# K1921VK035 register map
Vendor: NIIET; Series: K1921VKx; File version: 2.10
CPU: CM4 r0p1, little endian, MPU, FPU, 3 interrupt priority bits
Registers are 32-bit, read-write, reset 0x0 unless marked. A register's access mark holds for its fields unless they carry their own. Offsets are from the block's base; [hi:lo] are bit positions; lines under a group give offsets from that group; {n}, {i} and the like mark numbered series; 'fields as' and 'values as' point back to an identical list.

## RCU — Reset and clock unit registers
Base 0x40041000
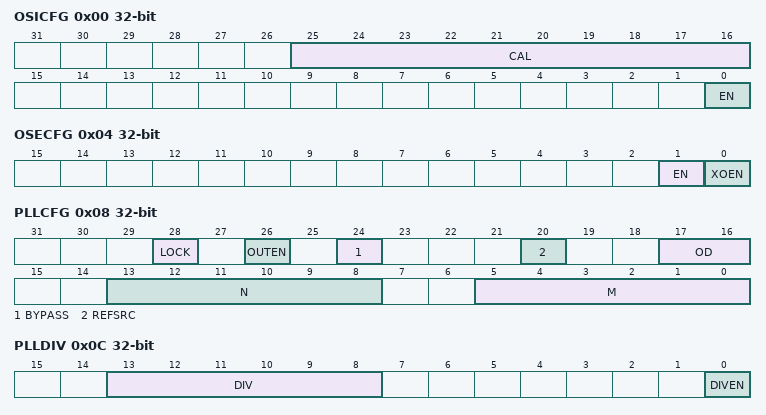
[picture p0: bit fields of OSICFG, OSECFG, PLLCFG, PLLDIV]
0x00 OSICFG — Internal oscillator configuration register
  [25:16] CAL — Oscillator 8MHz calibration value
  [0] EN — Oscillator 8MHz enable
0x04 OSECFG — External oscillator configuration register
  [1] EN — Enable external oscallator
  [0] XOEN — Enable output XO_OSC from external oscillator
0x08 PLLCFG — PLL configuration register
  [28] LOCK ro — PLL status lock
  [26] OUTEN — Enable PLL out
  [24] BYPASS — PLL Bypass enable
  [20] REFSRC — PLL Reference source select bit
    0=OSECLK (external oscillator); 1=OSICLK (internal oscillator)
  [17:16] OD — PLL OD Coefficient
    0=disabled; 1=Div2 (divide by 2); 2=Div4 (divide by 4); 3=Div8 (divide by 8)
  [13:8] N — PLL N Coefficient
  [5:0] M — PLL M Coefficient
0x0C PLLDIV — PLL divider register
  [13:8] DIV — PLL divider coefficent
  [0] DIVEN — PLL Divider enable bit
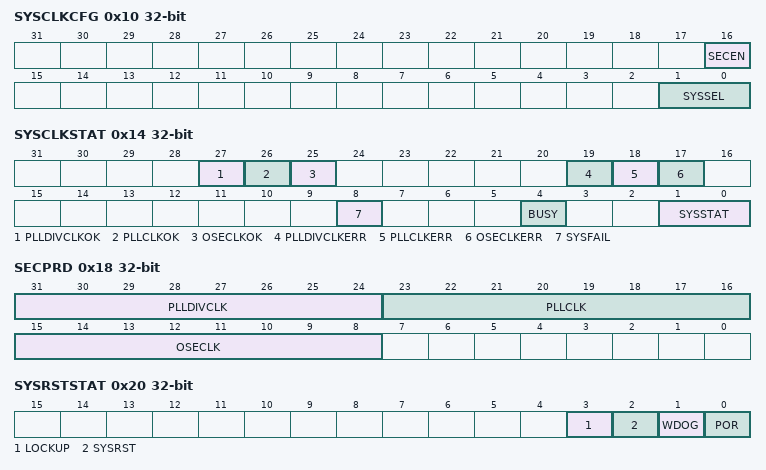
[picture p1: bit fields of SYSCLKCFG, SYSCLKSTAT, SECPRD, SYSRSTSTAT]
0x10 SYSCLKCFG — System clock configuration register
  [16] SECEN — Enable clock security system
  [1:0] SYSSEL — System clock source selection
    0=OSICLK (internal oscillator); 1=OSECLK (external oscillator); 2=PLLCLK (PLL output clock); 3=PLLDIVCLK (PLL divided clock)
0x14 SYSCLKSTAT ro — System clock status register
  [27] PLLDIVCLKOK — PLL divided clock good
  [26] PLLCLKOK — PLL clock good
  [25] OSECLKOK — External oscillator clock good
  [19] PLLDIVCLKERR — PLL divided clock fail
  [18] PLLCLKERR — PLL source clock fail
  [17] OSECLKERR — External oscillator clock fail
  [8] SYSFAIL — Error in current clock was detected
  [4] BUSY — Clock manager is busy, for example, when change clock source
  [1:0] SYSSTAT — Current system source clock
    on read: 0=OSICLK (internal oscillator); 1=OSECLK (external oscillator); 2=PLLCLK (PLL output clock); 3=PLLDIVCLK (PLL divided clock)
0x18 SECPRD — Security sysytem clock period register
  [31:24] PLLDIVCLK — Max counter value for PLL clock fail detection
  [23:16] PLLCLK — Max counter value for PLL clock fail detection
  [15:8] OSECLK — Max counter value for external oscillator clock fail detection
0x1C SYSRSTCFG — System reset configuration register
  [0] LOCKUPEN — Enable reset when processor in LOCKUP state
0x20 SYSRSTSTAT — Reset status register
  [3] LOCKUP — Lockup Reset Status
  [2] SYSRST — System Reset Status
  [1] WDOG — WatchDog Reset status
  [0] POR — PowerOn Reset status
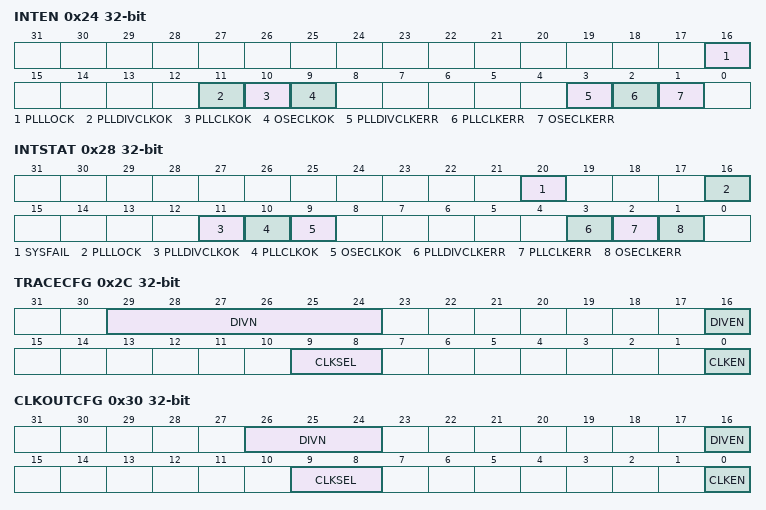
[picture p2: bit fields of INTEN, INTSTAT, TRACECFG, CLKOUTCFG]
0x24 INTEN — Interrupt enable register
  [16] PLLLOCK — Enable int from pll lock signal
  [11] PLLDIVCLKOK — Enable PLLDIVCLK good interrupt
  [10] PLLCLKOK — Enable PLLCLK good interrupt
  [9] OSECLKOK — Enable OSECLK good interrupt
  [3] PLLDIVCLKERR — Enable PLLDIVCLK fail interrupt
  [2] PLLCLKERR — Enable PLLCLK fail interrupt
  [1] OSECLKERR — Enable OSECLK fail interrupt
0x28 INTSTAT — Interrupt status register
  [20] SYSFAIL — Current clock failed status
  [16] PLLLOCK — Status pll lock signal
  [11] PLLDIVCLKOK — Status PLLDIV clock good signal
  [10] PLLCLKOK — Status PLL clock good signal
  [9] OSECLKOK — Status external oscillator clock good signal
  [3] PLLDIVCLKERR — Status PLLDIV clock fail signal
  [2] PLLCLKERR — Status PLL clock fail signal
  [1] OSECLKERR — Status external oscillator clock fail signal
0x2C TRACECFG — Trace clock configuration register
  [29:24] DIVN — Divider coefficient
  [16] DIVEN — Enable divider
  [9:8] CLKSEL — Clock source select
    values as SYSCLKCFG.SYSSEL
  [0] CLKEN — Clock enable
0x30 CLKOUTCFG — Clockout configuration register
  [26:24] DIVN — Divider coefficient
  [16] DIVEN — Enable divider
  [9:8] CLKSEL — Clock source select
    values as SYSCLKCFG.SYSSEL
  [0] CLKEN — Clock enable
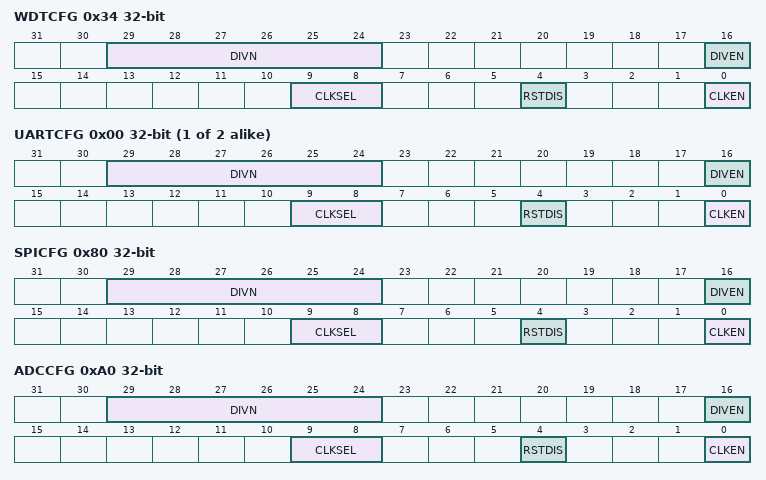
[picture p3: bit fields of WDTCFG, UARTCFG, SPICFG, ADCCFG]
0x34 WDTCFG — WatchDog configuration register
  [29:24] DIVN — Divider coefficient
  [16] DIVEN — Enable divider
  [9:8] CLKSEL — Clock source select
    values as SYSCLKCFG.SYSSEL
  [4] RSTDIS — Reset disable
  [0] CLKEN — Clock enable
{0x60+4i} UARTCFG[{i}] (i=0..1) group
  0x00 UARTCFG — UART clock and reset configuration register
    [29:24] DIVN — Divider coefficient
    [16] DIVEN — Enable divider
    [9:8] CLKSEL — Clock source select
      0=OSECLK (external oscillator); 1=PLLCLK (PLL output clock); 2=PLLDIVCLK (PLL divided clock); 3=OSICLK (internal oscillator)
    [4] RSTDIS — Reset disable
    [0] CLKEN — Clock enable
0x80 SPICFG — SPI clock and reset configuration register
  fields as UARTCFG[0].UARTCFG
0xA0 ADCCFG — ADC clock and reset configuration register
  fields as UARTCFG[0].UARTCFG
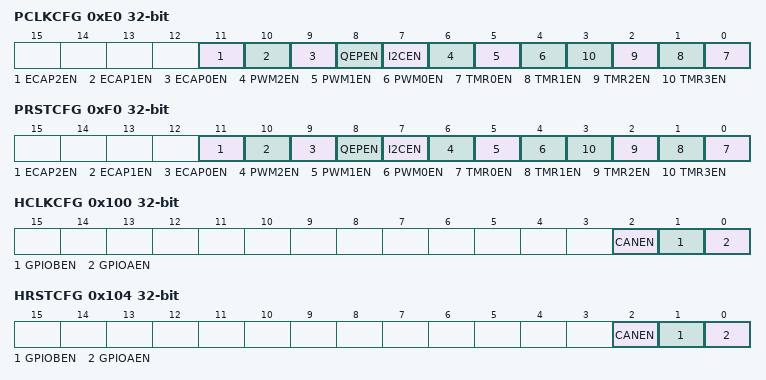
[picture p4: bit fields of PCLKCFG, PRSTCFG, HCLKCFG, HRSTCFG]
0xE0 PCLKCFG — APB clock configuration register
  [11] ECAP2EN — Enable clock for ECAP2
  [10] ECAP1EN — Enable clock for ECAP1
  [9] ECAP0EN — Enable clock for ECAP0
  [8] QEPEN — Enable clock for QEP
  [7] I2CEN — Enable clock for I2C
  [6] PWM2EN — Enable clock for PWM2
  [5] PWM1EN — Enable clock for PWM1
  [4] PWM0EN — Enable clock for PWM0
  [n] TMR{n}EN (n=0..3) — Enable clock for TMR{n}
0xF0 PRSTCFG — APB reset configuration register
  [11] ECAP2EN — Disable reset from ECAP2
  [10] ECAP1EN — Disable reset from ECAP1
  [9] ECAP0EN — Disable reset from ECAP0
  [8] QEPEN — Disable reset from QEP
  [7] I2CEN — Disable reset from I2C
  [6] PWM2EN — Disable reset from PWM2
  [5] PWM1EN — Disable reset from PWM1
  [4] PWM0EN — Disable reset from PWM0
  [n] TMR{n}EN (n=0..3) — Disable reset from TMR{n}
0x100 HCLKCFG — AHB clock configuration register
  [2] CANEN — Enable clock for CAN
  [1] GPIOBEN — Enable clock for GPIOB port
  [0] GPIOAEN — Enable clock for GPIOA port
0x104 HRSTCFG — AHB reset configuration register
  [2] CANEN — Disable reset from CAN
  [1] GPIOBEN — Disable reset from GPIOB port
  [0] GPIOAEN — Disable reset from GPIOA port
